# CC27x0 register map
File version: 1.0
CPU: CM4 r0p4, little endian, no MPU, no FPU, VTOR, 3 interrupt priority bits
Registers are 32-bit, read-write, reset 0x0 unless marked. A register's access mark holds for its fields unless they carry their own. Offsets are from the block's base; [hi:lo] are bit positions; {n}, {i} and the like mark numbered series; 'fields as' and 'values as' point back to an identical list.

## LRFDMDM (part 2 of 2)
Base 0x40082000
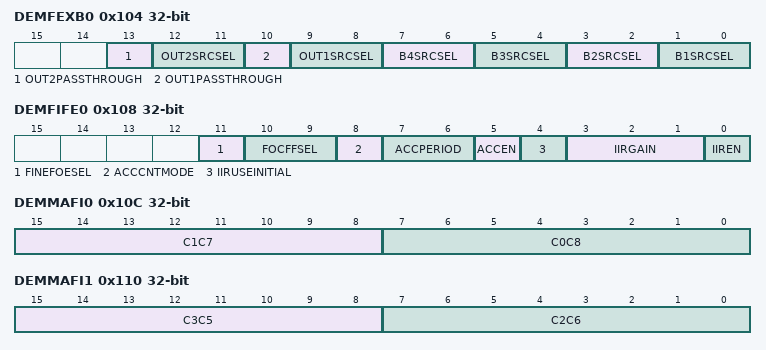
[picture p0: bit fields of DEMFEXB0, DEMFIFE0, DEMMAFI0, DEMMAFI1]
0x104 DEMFEXB0 — Internal. Only to be used through TI provided API.
  [13] OUT2PASSTHROUGH — Internal. Only to be used through TI provided API.
    1=ONE (Internal. Only to be used through TI provided API.); 0=ZERO (Internal. Only to be used through TI provided API.)
  [12:11] OUT2SRCSEL — Internal. Only to be used through TI provided API.
    2=BDE1 (Internal. Only to be used through TI provided API.); 1=CMIX (Internal. Only to be used through TI provided API.); 0=CODC (Internal. Only to be used through TI provided API.)
  [10] OUT1PASSTHROUGH — Internal. Only to be used through TI provided API.
    values as OUT2PASSTHROUGH
  [9:8] OUT1SRCSEL — Internal. Only to be used through TI provided API.
    values as OUT2SRCSEL
  [7:6] B4SRCSEL — Internal. Only to be used through TI provided API.
    3=ONES (Internal. Only to be used through TI provided API.); 0=ZEROS (Internal. Only to be used through TI provided API.)
  [5:4] B3SRCSEL — Internal. Only to be used through TI provided API.
    2=CMIX (Internal. Only to be used through TI provided API.); 1=CODC (Internal. Only to be used through TI provided API.); 0=INPUT (Internal. Only to be used through TI provided API.)
  [3:2] B2SRCSEL — Internal. Only to be used through TI provided API.
    2=BDE1 (Internal. Only to be used through TI provided API.); 1=CODC (Internal. Only to be used through TI provided API.); 0=INPUT (Internal. Only to be used through TI provided API.)
  [1:0] B1SRCSEL — Internal. Only to be used through TI provided API.
    2=BDE1 (Internal. Only to be used through TI provided API.); 1=CMIX (Internal. Only to be used through TI provided API.); 0=INPUT (Internal. Only to be used through TI provided API.)
0x108 DEMFIFE0 — Internal. Only to be used through TI provided API.
  [11] FINEFOESEL — Internal. Only to be used through TI provided API.
    1=ACC (Internal. Only to be used through TI provided API.); 0=IIR (Internal. Only to be used through TI provided API.)
  [10:9] FOCFFSEL — Internal. Only to be used through TI provided API.
    2=MANUAL (Internal. Only to be used through TI provided API.); 1=ACC (Internal. Only to be used through TI provided API.); 0=IIR (Internal. Only to be used through TI provided API.)
  [8] ACCCNTMODE — Internal. Only to be used through TI provided API.
    1=CONT (Internal. Only to be used through TI provided API.); 0=SINGLE (Internal. Only to be used through TI provided API.)
  [7:6] ACCPERIOD — Internal. Only to be used through TI provided API.
    3=PER512 (Internal. Only to be used through TI provided API.); 2=PER256 (Internal. Only to be used through TI provided API.); 1=PER128 (Internal. Only to be used through TI provided API.); 0=PER64 (Internal. Only to be used through TI provided API.)
  [5] ACCEN — Internal. Only to be used through TI provided API.
    1=ON (Internal. Only to be used through TI provided API.); 0=OFF (Internal. Only to be used through TI provided API.)
  [4] IIRUSEINITIAL — Internal. Only to be used through TI provided API.
    1=EN (Internal. Only to be used through TI provided API.); 0=DIS (Internal. Only to be used through TI provided API.)
  [3:1] IIRGAIN — Internal. Only to be used through TI provided API.
    7=DIV1024 (Internal. Only to be used through TI provided API.); 6=DIV512 (Internal. Only to be used through TI provided API.); 5=DIV256 (Internal. Only to be used through TI provided API.); 4=DIV128 (Internal. Only to be used through TI provided API.); 3=DIV64 (Internal. Only to be used through TI provided API.); 2=DIV32 (Internal. Only to be used through TI provided API.); 1=DIV16 (Internal. Only to be used through TI provided API.); 0=OFF (Internal. Only to be used through TI provided API.)
  [0] IIREN — Internal. Only to be used through TI provided API.
    values as ACCEN
0x10C DEMMAFI0 — Internal. Only to be used through TI provided API.
  [15:8] C1C7 — Internal. Only to be used through TI provided API.
    255=ALLONES (Internal. Only to be used through TI provided API.); 0=ALLZEROS (Internal. Only to be used through TI provided API.)
  [7:0] C0C8 — Internal. Only to be used through TI provided API.
    values as C1C7
0x110 DEMMAFI1 — Internal. Only to be used through TI provided API.
  [15:8] C3C5 — Internal. Only to be used through TI provided API.
    values as DEMMAFI0.C1C7
  [7:0] C2C6 — Internal. Only to be used through TI provided API.
    values as DEMMAFI0.C1C7
0x114 DEMMAFI2 — Internal. Only to be used through TI provided API.
  [8:0] C4
    0x1FF=ALLONES (Internal. Only to be used through TI provided API.); 0=ALLZEROS (Internal. Only to be used through TI provided API.)
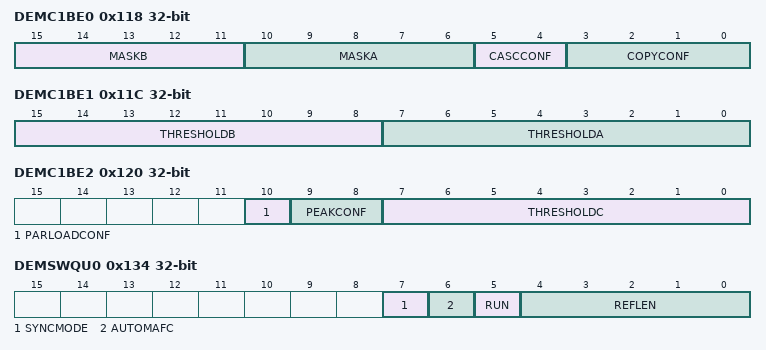
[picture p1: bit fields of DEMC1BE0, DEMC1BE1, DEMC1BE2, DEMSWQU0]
0x118 DEMC1BE0 — Internal. Only to be used through TI provided API.
  [15:11] MASKB — Internal. Only to be used through TI provided API.
    31=ALLONES (Internal. Only to be used through TI provided API.); 0=ALLZEROS (Internal. Only to be used through TI provided API.)
  [10:6] MASKA — Internal. Only to be used through TI provided API.
    values as MASKB
  [5:4] CASCCONF — Internal. Only to be used through TI provided API.
    2=PARALLEL (Internal. Only to be used through TI provided API.); 1=SERIAL (Internal. Only to be used through TI provided API.); 0=SINGLE (Internal. Only to be used through TI provided API.)
  [3:0] COPYCONF — Internal. Only to be used through TI provided API.
    15=ALLONES (Internal. Only to be used through TI provided API.); 0=ALLZEROS (Internal. Only to be used through TI provided API.)
0x11C DEMC1BE1 — Internal. Only to be used through TI provided API.
  [15:8] THRESHOLDB — Internal. Only to be used through TI provided API.
    values as DEMMAFI0.C1C7
  [7:0] THRESHOLDA — Internal. Only to be used through TI provided API.
    values as DEMMAFI0.C1C7
0x120 DEMC1BE2 — Internal. Only to be used through TI provided API.
  [10] PARLOADCONF — Internal. Only to be used through TI provided API.
    1=ATOD (Internal. Only to be used through TI provided API.); 0=ATOB (Internal. Only to be used through TI provided API.)
  [9:8] PEAKCONF — Internal. Only to be used through TI provided API.
    2=BESTAB (Internal. Only to be used through TI provided API.); 1=BEST (Internal. Only to be used through TI provided API.); 0=THRESH (Internal. Only to be used through TI provided API.)
  [7:0] THRESHOLDC — Internal. Only to be used through TI provided API.
    values as DEMMAFI0.C1C7
{0x124+4i} SPARE{i} (i=0..3) — Internal. Only to be used through TI provided API.
  [15:0] VAL
    0xFFFF=ALLONES (Internal. Only to be used through TI provided API.); 0=ALLZEROS (Internal. Only to be used through TI provided API.)
0x134 DEMSWQU0 — Internal. Only to be used through TI provided API.
  [7] SYNCMODE — Internal. Only to be used through TI provided API.
    values as DEMFEXB0.OUT2PASSTHROUGH
  [6] AUTOMAFC — Internal. Only to be used through TI provided API.
    values as DEMFIFE0.ACCEN
  [5] RUN — Internal. Only to be used through TI provided API.
    values as DEMFIFE0.ACCEN
  [4:0] REFLEN — Internal. Only to be used through TI provided API.
    values as DEMC1BE0.MASKB
0x138 DEMC1BEREF0 — Internal. Only to be used through TI provided API.
  [15:0] CAR15C0
    values as SPARE0.VAL
0x13C DEMC1BEREF1 — Internal. Only to be used through TI provided API.
  [15:0] CAR31C16
    values as SPARE0.VAL
0x140 DEMC1BEREF2 — Internal. Only to be used through TI provided API.
  [15:0] CBR15C0
    values as SPARE0.VAL
0x144 DEMC1BEREF3 — Internal. Only to be used through TI provided API.
  [15:0] CBR31C16
    values as SPARE0.VAL
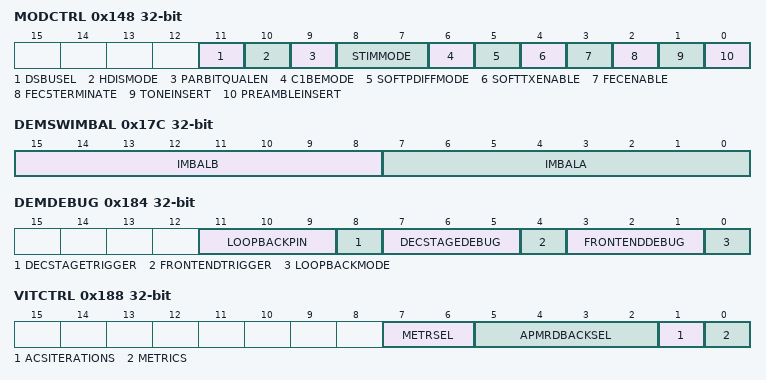
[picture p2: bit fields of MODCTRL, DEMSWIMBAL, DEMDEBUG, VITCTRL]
0x148 MODCTRL — Internal. Only to be used through TI provided API.
  [11] DSBUSEL — Internal. Only to be used through TI provided API.
    values as DEMFEXB0.OUT2PASSTHROUGH
  [10] HDISMODE — Internal. Only to be used through TI provided API.
    values as DEMFIFE0.IIRUSEINITIAL
  [9] PARBITQUALEN — Internal. Only to be used through TI provided API.
    values as DEMFIFE0.ACCEN
  [8:7] STIMMODE — Internal. Only to be used through TI provided API.
    2=EARLY (Internal. Only to be used through TI provided API.); 1=LATE (Internal. Only to be used through TI provided API.); 0=NORMAL (Internal. Only to be used through TI provided API.)
  [6] C1BEMODE — Internal. Only to be used through TI provided API.
    1=EARLYLATE (Internal. Only to be used through TI provided API.); 0=NORMAL (Internal. Only to be used through TI provided API.)
  [5] SOFTPDIFFMODE — Internal. Only to be used through TI provided API.
    values as DEMFIFE0.IIRUSEINITIAL
  [4] SOFTTXENABLE — Internal. Only to be used through TI provided API.
    values as DEMFIFE0.ACCEN
  [3] FECENABLE — Internal. Only to be used through TI provided API.
    values as DEMFIFE0.ACCEN
  [2] FEC5TERMINATE — Internal. Only to be used through TI provided API.
    values as DEMFIFE0.ACCEN
  [1] TONEINSERT — Internal. Only to be used through TI provided API.
    values as DEMFIFE0.IIRUSEINITIAL
  [0] PREAMBLEINSERT — Internal. Only to be used through TI provided API.
    values as DEMFIFE0.IIRUSEINITIAL
0x14C MODPREAMBLE — Internal. Only to be used through TI provided API.
  [15:0] WORD
    values as SPARE0.VAL
0x150 DEMFRAC0 — Internal. Only to be used through TI provided API.
  [15:0] P15C0
    values as SPARE0.VAL
0x154 DEMFRAC1 — Internal. Only to be used through TI provided API.
  [11:0] P27C16
    0xFFF=ALLONES (Internal. Only to be used through TI provided API.); 0=ALLZEROS (Internal. Only to be used through TI provided API.)
0x158 DEMFRAC2 — Internal. Only to be used through TI provided API.
  [15:0] Q15C0
    values as SPARE0.VAL
0x15C DEMFRAC3 — Internal. Only to be used through TI provided API.
  [11:0] Q27C16
    values as DEMFRAC1.P27C16
0x160 DEMCODC1 — Internal. Only to be used through TI provided API.
  [12:0] COMPIVAL
    0x1FFF=ALLONES (Internal. Only to be used through TI provided API.); 0=ALLZEROS (Internal. Only to be used through TI provided API.)
0x164 DEMCODC2 — Internal. Only to be used through TI provided API.
  [12:0] COMPQVAL
    values as DEMCODC1.COMPIVAL
0x168 DEMFIDC1 — Internal. Only to be used through TI provided API.
  fields as DEMCODC1
0x16C DEMFIDC2 — Internal. Only to be used through TI provided API.
  fields as DEMCODC2
0x170 DEMFIFE1 — Internal. Only to be used through TI provided API.
  [7:0] FOCFBREGVAL
    values as DEMMAFI0.C1C7
0x174 DEMMAFC0 — Internal. Only to be used through TI provided API.
  [7:0] COMPVAL
    values as DEMMAFI0.C1C7
0x178 DEMMAFI4 — Internal. Only to be used through TI provided API.
  [7:0] TERMVAL
    values as DEMMAFI0.C1C7
0x17C DEMSWIMBAL — Internal. Only to be used through TI provided API.
  [15:8] IMBALB — Internal. Only to be used through TI provided API.
    values as DEMMAFI0.C1C7
  [7:0] IMBALA — Internal. Only to be used through TI provided API.
    values as DEMMAFI0.C1C7
0x180 DEMSOFTPDIFF — Internal. Only to be used through TI provided API.
  [7:0] VAL
    values as DEMMAFI0.C1C7
0x184 DEMDEBUG — Internal. Only to be used through TI provided API.
  [11:9] LOOPBACKPIN — Internal. Only to be used through TI provided API.
    {v}=GPI{v} (Internal. Only to be used through TI provided API.) (v=0..7)
  [8] DECSTAGETRIGGER — Internal. Only to be used through TI provided API.
    values as DEMFEXB0.OUT2PASSTHROUGH
  [7:5] DECSTAGEDEBUG — Internal. Only to be used through TI provided API.
    7=SOFD (Internal. Only to be used through TI provided API.); 6=STIM (Internal. Only to be used through TI provided API.); 5=MAFC (Internal. Only to be used through TI provided API.); 4=C1BE (Internal. Only to be used through TI provided API.); 3=MAFI (Internal. Only to be used through TI provided API.); 2=FIFE (Internal. Only to be used through TI provided API.); 1=PDIF (Internal. Only to be used through TI provided API.); 0=NOSEL (Internal. Only to be used through TI provided API.)
  [4] FRONTENDTRIGGER — Internal. Only to be used through TI provided API.
    values as DEMFEXB0.OUT2PASSTHROUGH
  [3:1] FRONTENDDEBUG — Internal. Only to be used through TI provided API.
    7=FIDC (Internal. Only to be used through TI provided API.); 6=FRAC (Internal. Only to be used through TI provided API.); 5=CHFI (Internal. Only to be used through TI provided API.); 4=BDE2 (Internal. Only to be used through TI provided API.); 3=FEXB2 (Internal. Only to be used through TI provided API.); 2=BDE1 (Internal. Only to be used through TI provided API.); 1=IQMC (Internal. Only to be used through TI provided API.); 0=NOSEL (Internal. Only to be used through TI provided API.)
  [0] LOOPBACKMODE — Internal. Only to be used through TI provided API.
    values as DEMFEXB0.OUT2PASSTHROUGH
0x188 VITCTRL — Internal. Only to be used through TI provided API.
  [7:6] METRSEL — Internal. Only to be used through TI provided API.
    3=MLSE (Internal. Only to be used through TI provided API.); 2=SOFD (Internal. Only to be used through TI provided API.); 1=PHAC (Internal. Only to be used through TI provided API.); 0=MET5M (Internal. Only to be used through TI provided API.)
  [5:2] APMRDBACKSEL — Internal. Only to be used through TI provided API.
    {v}=APM{v-8} (Internal. Only to be used through TI provided API.) (v=8..15); 0=NOSEL (Internal. Only to be used through TI provided API.)
  [1] ACSITERATIONS — Internal. Only to be used through TI provided API.
    1=CODE23 (Internal. Only to be used through TI provided API.); 0=CODE12 (Internal. Only to be used through TI provided API.)
  [0] METRICS — Internal. Only to be used through TI provided API.
    1=SOFT (Internal. Only to be used through TI provided API.); 0=HW (Internal. Only to be used through TI provided API.)
0x18C VITCOMPUTE wo — Internal. Only to be used through TI provided API.
  [0] START
    values as DEMFEXB0.OUT2PASSTHROUGH
0x190 VITAPMRDBACK ro — Internal. Only to be used through TI provided API.
  [9:0] VALUE
    0x3FF=ALLONES (Internal. Only to be used through TI provided API.); 0=ALLZEROS (Internal. Only to be used through TI provided API.)
0x194 VITSTATE ro — Internal. Only to be used through TI provided API.
  [2:0] VALUE
    7=ALLONES (Internal. Only to be used through TI provided API.); 0=ALLZEROS (Internal. Only to be used through TI provided API.)
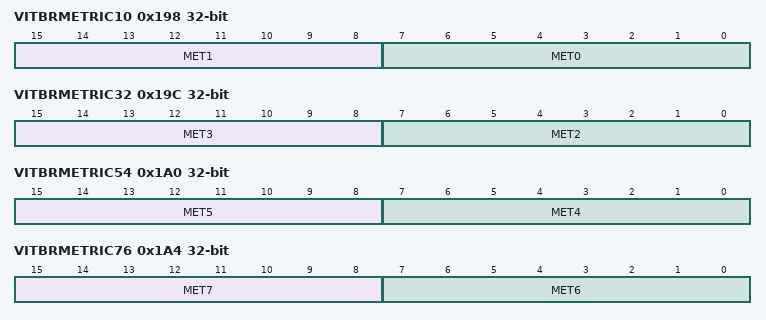
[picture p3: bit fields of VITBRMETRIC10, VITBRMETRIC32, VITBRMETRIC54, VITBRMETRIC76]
0x198 VITBRMETRIC10 — Internal. Only to be used through TI provided API.
  [15:8] MET1 — Internal. Only to be used through TI provided API.
    values as DEMMAFI0.C1C7
  [7:0] MET0 — Internal. Only to be used through TI provided API.
    values as DEMMAFI0.C1C7
0x19C VITBRMETRIC32 — Internal. Only to be used through TI provided API.
  [15:8] MET3 — Internal. Only to be used through TI provided API.
    values as DEMMAFI0.C1C7
  [7:0] MET2 — Internal. Only to be used through TI provided API.
    values as DEMMAFI0.C1C7
0x1A0 VITBRMETRIC54 — Internal. Only to be used through TI provided API.
  [15:8] MET5 — Internal. Only to be used through TI provided API.
    values as DEMMAFI0.C1C7
  [7:0] MET4 — Internal. Only to be used through TI provided API.
    values as DEMMAFI0.C1C7
0x1A4 VITBRMETRIC76 — Internal. Only to be used through TI provided API.
  [15:8] MET7 — Internal. Only to be used through TI provided API.
    values as DEMMAFI0.C1C7
  [7:0] MET6 — Internal. Only to be used through TI provided API.
    values as DEMMAFI0.C1C7
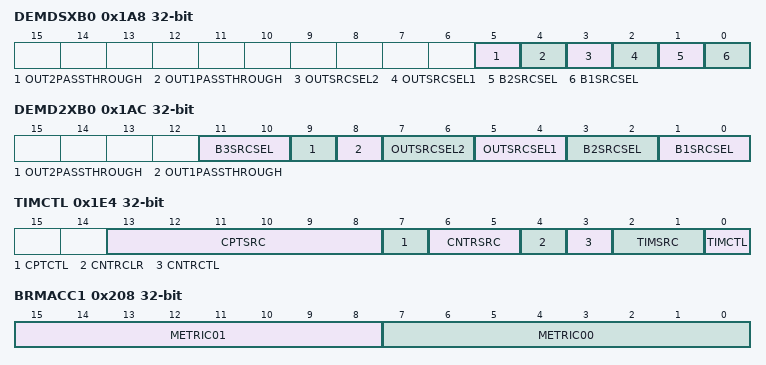
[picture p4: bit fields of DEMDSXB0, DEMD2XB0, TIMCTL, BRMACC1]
0x1A8 DEMDSXB0 — Internal. Only to be used through TI provided API.
  [5] OUT2PASSTHROUGH — Internal. Only to be used through TI provided API.
    values as DEMFEXB0.OUT2PASSTHROUGH
  [4] OUT1PASSTHROUGH — Internal. Only to be used through TI provided API.
    values as DEMFEXB0.OUT2PASSTHROUGH
  [3] OUTSRCSEL2 — Internal. Only to be used through TI provided API.
    1=MAFI (Internal. Only to be used through TI provided API.); 0=FIFE (Internal. Only to be used through TI provided API.)
  [2] OUTSRCSEL1 — Internal. Only to be used through TI provided API.
    values as OUTSRCSEL2
  [1] B2SRCSEL — Internal. Only to be used through TI provided API.
    1=FIFE (Internal. Only to be used through TI provided API.); 0=INPUT (Internal. Only to be used through TI provided API.)
  [0] B1SRCSEL — Internal. Only to be used through TI provided API.
    1=MAFI (Internal. Only to be used through TI provided API.); 0=INPUT (Internal. Only to be used through TI provided API.)
0x1AC DEMD2XB0 — Internal. Only to be used through TI provided API.
  [11:10] B3SRCSEL — Internal. Only to be used through TI provided API.
    2=STIM (Internal. Only to be used through TI provided API.); 1=MAFC (Internal. Only to be used through TI provided API.); 0=INPUT (Internal. Only to be used through TI provided API.)
  [9] OUT2PASSTHROUGH — Internal. Only to be used through TI provided API.
  [8] OUT1PASSTHROUGH — Internal. Only to be used through TI provided API.
  [7:6] OUTSRCSEL2 — Internal. Only to be used through TI provided API.
    2=PDIF2 (Internal. Only to be used through TI provided API.); 1=STIM (Internal. Only to be used through TI provided API.); 0=MAFC (Internal. Only to be used through TI provided API.)
  [5:4] OUTSRCSEL1 — Internal. Only to be used through TI provided API.
    values as OUTSRCSEL2
  [3:2] B2SRCSEL — Internal. Only to be used through TI provided API.
    2=PDIF2 (Internal. Only to be used through TI provided API.); 1=MAFC (Internal. Only to be used through TI provided API.); 0=INPUT (Internal. Only to be used through TI provided API.)
  [1:0] B1SRCSEL — Internal. Only to be used through TI provided API.
    2=PDIF2 (Internal. Only to be used through TI provided API.); 1=STIM (Internal. Only to be used through TI provided API.); 0=INPUT (Internal. Only to be used through TI provided API.)
0x1E4 TIMCTL — Internal. Only to be used through TI provided API.
  [13:8] CPTSRC — Internal. Only to be used through TI provided API.
    63=ALLONES (Internal. Only to be used through TI provided API.); 0=ALLZEROS (Internal. Only to be used through TI provided API.)
  [7] CPTCTL — Internal. Only to be used through TI provided API.
    values as DEMFIFE0.IIRUSEINITIAL
  [6:5] CNTRSRC — Internal. Only to be used through TI provided API.
    3=CLK4BAUDF (Internal. Only to be used through TI provided API.); 2=CLK4BAUD (Internal. Only to be used through TI provided API.); 1=CLKBAUD (Internal. Only to be used through TI provided API.); 0=CLK (Internal. Only to be used through TI provided API.)
  [4] CNTRCLR — Internal. Only to be used through TI provided API.
    values as DEMFEXB0.OUT2PASSTHROUGH
  [3] CNTRCTL — Internal. Only to be used through TI provided API.
    values as DEMFEXB0.OUT2PASSTHROUGH
  [2:1] TIMSRC — Internal. Only to be used through TI provided API.
    values as CNTRSRC
  [0] TIMCTL — Internal. Only to be used through TI provided API.
    values as DEMFIFE0.IIRUSEINITIAL
0x1E8 TIMINC — Internal. Only to be used through TI provided API.
  fields as SPARE0
0x1EC TIMPER — Internal. Only to be used through TI provided API.
  fields as SPARE0
0x1F0 TIMCNT ro — Internal. Only to be used through TI provided API.
  fields as SPARE0
0x1F4 TIMCAPT ro — Internal. Only to be used through TI provided API.
  [15:0] VALUE
    values as SPARE0.VAL
0x1F8 TIMEBASE wo — Internal. Only to be used through TI provided API.
  [0] FLUSH
    values as DEMFEXB0.OUT2PASSTHROUGH
0x1FC COUNT1IN — Internal. Only to be used through TI provided API.
  fields as SPARE0
0x200 COUNT1RES ro — Internal. Only to be used through TI provided API.
  [4:0] VAL
    values as DEMC1BE0.MASKB
0x208 BRMACC1 ro — Internal. Only to be used through TI provided API.
  [15:8] METRIC01 — Internal. Only to be used through TI provided API.
    values as DEMMAFI0.C1C7
  [7:0] METRIC00 — Internal. Only to be used through TI provided API.
    values as DEMMAFI0.C1C7
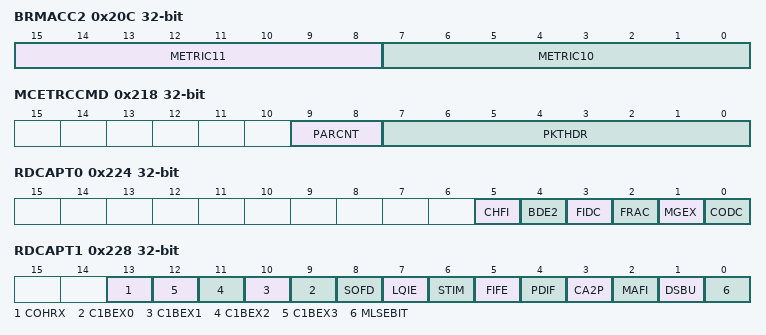
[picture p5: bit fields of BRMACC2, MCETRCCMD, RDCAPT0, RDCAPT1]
0x20C BRMACC2 ro — Internal. Only to be used through TI provided API.
  [15:8] METRIC11 — Internal. Only to be used through TI provided API.
    values as DEMMAFI0.C1C7
  [7:0] METRIC10 — Internal. Only to be used through TI provided API.
    values as DEMMAFI0.C1C7
0x210 MCETRCCTRL wo — Internal. Only to be used through TI provided API.
  [0] SEND
    values as DEMFEXB0.OUT2PASSTHROUGH
0x214 MCETRCSTAT ro — Internal. Only to be used through TI provided API.
  [0] BUSY
    values as DEMFEXB0.OUT2PASSTHROUGH
0x218 MCETRCCMD — Internal. Only to be used through TI provided API.
  [9:8] PARCNT — Internal. Only to be used through TI provided API.
    3=ALLONES (Internal. Only to be used through TI provided API.); 0=ALLZEROS (Internal. Only to be used through TI provided API.)
  [7:0] PKTHDR — Internal. Only to be used through TI provided API.
    values as DEMMAFI0.C1C7
0x21C MCETRCPAR0 — Internal. Only to be used through TI provided API.
  fields as SPARE0
0x220 MCETRCPAR1 — Internal. Only to be used through TI provided API.
  fields as SPARE0
0x224 RDCAPT0 wo — Internal. Only to be used through TI provided API.
  [all] fields
    values as DEMFEXB0.OUT2PASSTHROUGH
  [5] CHFI — Internal. Only to be used through TI provided API.
  [4] BDE2 — Internal. Only to be used through TI provided API.
  [3] FIDC — Internal. Only to be used through TI provided API.
  [2] FRAC — Internal. Only to be used through TI provided API.
  [1] MGEX — Internal. Only to be used through TI provided API.
  [0] CODC — Internal. Only to be used through TI provided API.
0x228 RDCAPT1 wo — Internal. Only to be used through TI provided API.
  [all] fields
    values as DEMFEXB0.OUT2PASSTHROUGH
  [13] COHRX — Internal. Only to be used through TI provided API.
  [n+9] C1BEX{n} (n=0..3) — Internal. Only to be used through TI provided API.
  [8] SOFD — Internal. Only to be used through TI provided API.
  [7] LQIE — Internal. Only to be used through TI provided API.
  [6] STIM — Internal. Only to be used through TI provided API.
  [5] FIFE — Internal. Only to be used through TI provided API.
  [4] PDIF — Internal. Only to be used through TI provided API.
  [3] CA2P — Internal. Only to be used through TI provided API.
  [2] MAFI — Internal. Only to be used through TI provided API.
  [1] DSBU — Internal. Only to be used through TI provided API.
  [0] MLSEBIT — Internal. Only to be used through TI provided API.
0x22C FECAPT0 — Internal. Only to be used through TI provided API.
  [12:0] VAL
    values as DEMCODC1.COMPIVAL
0x230 FECAPT1 — Internal. Only to be used through TI provided API.
  fields as FECAPT0
{0x234+4i} DSCAPT{i} (i=0..3) — Internal. Only to be used through TI provided API.
  fields as DEMSOFTPDIFF
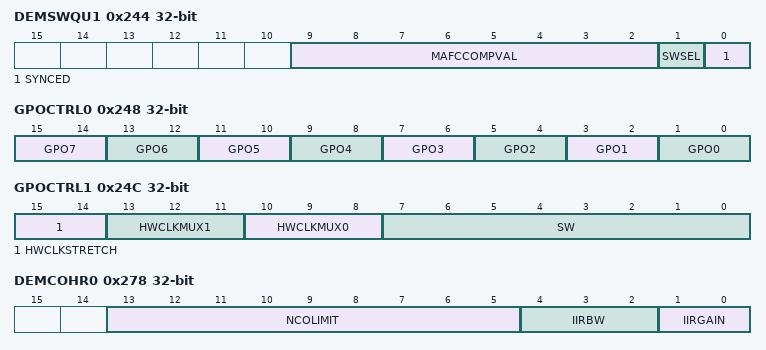
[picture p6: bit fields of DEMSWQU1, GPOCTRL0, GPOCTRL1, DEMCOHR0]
0x244 DEMSWQU1 — Internal. Only to be used through TI provided API.
  [9:2] MAFCCOMPVAL ro — Internal. Only to be used through TI provided API.
    values as DEMMAFI0.C1C7
  [1] SWSEL ro — Internal. Only to be used through TI provided API.
    1=B (Internal. Only to be used through TI provided API.); 0=A (Internal. Only to be used through TI provided API.)
  [0] SYNCED ro — Internal. Only to be used through TI provided API.
    values as DEMFEXB0.OUT2PASSTHROUGH
0x248 GPOCTRL0 — Internal. Only to be used through TI provided API.
  [15:14] GPO7 — Internal. Only to be used through TI provided API.
    3=THREE (Internal. Only to be used through TI provided API.); 2=TWO (Internal. Only to be used through TI provided API.); 1=TOPSM_WAIT (Internal. Only to be used through TI provided API.); 0=SW7 (Internal. Only to be used through TI provided API.)
  [13:12] GPO6 — Internal. Only to be used through TI provided API.
    3=THREE (Internal. Only to be used through TI provided API.); 2=TWO (Internal. Only to be used through TI provided API.); 1=TRANSPARENT_OUT (Internal. Only to be used through TI provided API.); 0=SW6 (Internal. Only to be used through TI provided API.)
  [11:10] GPO5 — Internal. Only to be used through TI provided API.
    3=THREE (Internal. Only to be used through TI provided API.); 2=TWO (Internal. Only to be used through TI provided API.); 1=DEM_OUT_WORD (Internal. Only to be used through TI provided API.); 0=SW5 (Internal. Only to be used through TI provided API.)
  [9:8] GPO4 — Internal. Only to be used through TI provided API.
    3=THREE (Internal. Only to be used through TI provided API.); 2=TWO (Internal. Only to be used through TI provided API.); 1=CORR_PEAK_C (Internal. Only to be used through TI provided API.); 0=SW4 (Internal. Only to be used through TI provided API.)
  [7:6] GPO3 — Internal. Only to be used through TI provided API.
    3=THREE (Internal. Only to be used through TI provided API.); 2=TWO (Internal. Only to be used through TI provided API.); 1=CORR_PEAK_B (Internal. Only to be used through TI provided API.); 0=SW3 (Internal. Only to be used through TI provided API.)
  [5:4] GPO2 — Internal. Only to be used through TI provided API.
    3=THREE (Internal. Only to be used through TI provided API.); 2=TWO (Internal. Only to be used through TI provided API.); 1=CORR_PEAK_A (Internal. Only to be used through TI provided API.); 0=SW2 (Internal. Only to be used through TI provided API.)
  [3:2] GPO1 — Internal. Only to be used through TI provided API.
    3=THREE (Internal. Only to be used through TI provided API.); 2=TWO (Internal. Only to be used through TI provided API.); 1=HWCLK1 (Internal. Only to be used through TI provided API.); 0=SW1 (Internal. Only to be used through TI provided API.)
  [1:0] GPO0 — Internal. Only to be used through TI provided API.
    3=THREE (Internal. Only to be used through TI provided API.); 2=LOOPBACK (Internal. Only to be used through TI provided API.); 1=HWCLK0 (Internal. Only to be used through TI provided API.); 0=SW0 (Internal. Only to be used through TI provided API.)
0x24C GPOCTRL1 — Internal. Only to be used through TI provided API.
  [all] fields
    values as DEMFEXB0.OUT2PASSTHROUGH
  [15:14] HWCLKSTRETCH — Internal. Only to be used through TI provided API.
  [13:11] HWCLKMUX1 — Internal. Only to be used through TI provided API.
  [10:8] HWCLKMUX0 — Internal. Only to be used through TI provided API.
  [7:0] SW — Internal. Only to be used through TI provided API.
0x250 RFERSSI ro — Internal. Only to be used through TI provided API.
  fields as DEMSOFTPDIFF
0x254 RFEMAXRSSI ro — Internal. Only to be used through TI provided API.
  fields as DEMSOFTPDIFF
0x258 RFEDBGAIN ro — Internal. Only to be used through TI provided API.
  fields as DEMSOFTPDIFF
0x25C SYNC0 ro — Internal. Only to be used through TI provided API.
  [15:0] SWA15C0
    values as SPARE0.VAL
0x260 SYNC1 ro — Internal. Only to be used through TI provided API.
  [15:0] SWA31C16
    values as SPARE0.VAL
0x264 SYNC2 ro — Internal. Only to be used through TI provided API.
  [15:0] SWB15C0
    values as SPARE0.VAL
0x268 SYNC3 ro — Internal. Only to be used through TI provided API.
  [15:0] SWB31C16
    values as SPARE0.VAL
0x274 DEMHDIS0 ro — Internal. Only to be used through TI provided API.
  [7:0] VAL
0x278 DEMCOHR0 — Internal. Only to be used through TI provided API.
  [13:5] NCOLIMIT — Internal. Only to be used through TI provided API.
  [4:2] IIRBW — Internal. Only to be used through TI provided API.
  [1:0] IIRGAIN — Internal. Only to be used through TI provided API.
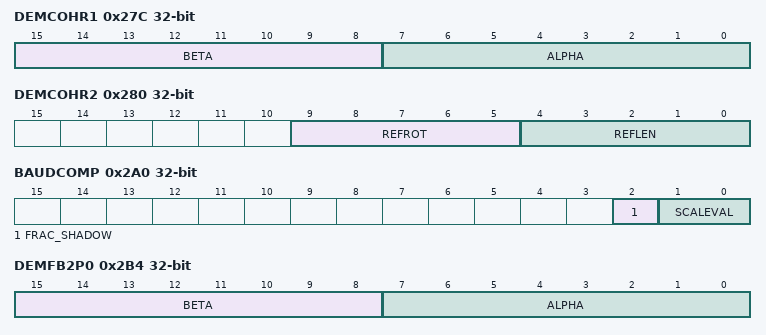
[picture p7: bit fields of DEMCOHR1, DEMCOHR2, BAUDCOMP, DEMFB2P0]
0x27C DEMCOHR1 — Internal. Only to be used through TI provided API.
  [15:8] BETA — Internal. Only to be used through TI provided API.
  [7:0] ALPHA — Internal. Only to be used through TI provided API.
0x280 DEMCOHR2 — Internal. Only to be used through TI provided API.
  [9:5] REFROT — Internal. Only to be used through TI provided API.
  [4:0] REFLEN — Internal. Only to be used through TI provided API.
0x284 DEMCOHR3 — Internal. Only to be used through TI provided API.
  [15:0] REF150
0x288 DEMCOHR4 — Internal. Only to be used through TI provided API.
  [15:0] REF3116
0x28C DEMCOHR5 ro — Internal. Only to be used through TI provided API.
  [15:0] VAL
0x290 DEMCOHR6 ro — Internal. Only to be used through TI provided API.
  [5:0] VAL
0x294 DEMCOHR7 ro — Internal. Only to be used through TI provided API.
  [3:0] VAL
0x298 DEMCOHR8 ro — Internal. Only to be used through TI provided API.
  [5:0] VAL
0x29C DEMCOHR9 ro — Internal. Only to be used through TI provided API.
  [12:0] VAL
0x2A0 BAUDCOMP — Internal. Only to be used through TI provided API.
  [2] FRAC_SHADOW — Internal. Only to be used through TI provided API.
  [1:0] SCALEVAL — Internal. Only to be used through TI provided API.
0x2B0 DEMCMIX2 — Internal. Only to be used through TI provided API.
  [12:0] N
0x2B4 DEMFB2P0 — Internal. Only to be used through TI provided API.
  fields as DEMCOHR1
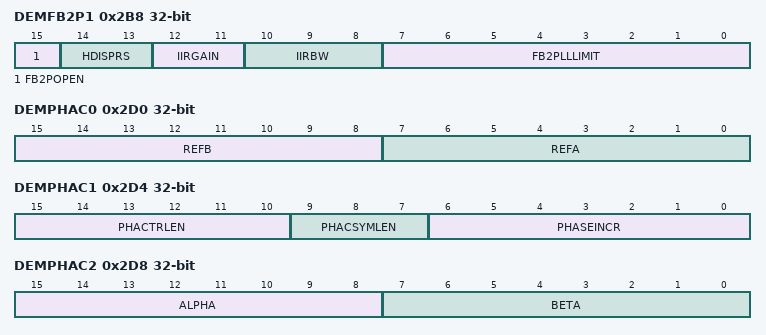
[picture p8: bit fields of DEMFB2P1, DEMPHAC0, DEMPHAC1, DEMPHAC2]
0x2B8 DEMFB2P1 — Internal. Only to be used through TI provided API.
  [15] FB2POPEN — Internal. Only to be used through TI provided API.
  [14:13] HDISPRS — Internal. Only to be used through TI provided API.
  [12:11] IIRGAIN — Internal. Only to be used through TI provided API.
  [10:8] IIRBW — Internal. Only to be used through TI provided API.
  [7:0] FB2PLLLIMIT — Internal. Only to be used through TI provided API.
0x2BC DEMFB2P2 — Internal. Only to be used through TI provided API.
  [10:0] RBP ro
0x2C4 DEMDSBU0 ro reset 0x1FF — Internal. Only to be used through TI provided API.
  [8:0] RDPOUT
0x2C8 DEMDSBU1 ro — Internal. Only to be used through TI provided API.
  [15:0] AVGVAL
0x2CC DEMDSBU3 ro — Internal. Only to be used through TI provided API.
  [8:0] WRPOUT
0x2D0 DEMPHAC0 — Internal. Only to be used through TI provided API.
  [15:8] REFB — Internal. Only to be used through TI provided API.
  [7:0] REFA — Internal. Only to be used through TI provided API.
0x2D4 DEMPHAC1 — Internal. Only to be used through TI provided API.
  [15:10] PHACTRLEN — Internal. Only to be used through TI provided API.
  [9:7] PHACSYMLEN — Internal. Only to be used through TI provided API.
  [6:0] PHASEINCR — Internal. Only to be used through TI provided API.
0x2D8 DEMPHAC2 — Internal. Only to be used through TI provided API.
  [15:8] ALPHA — Internal. Only to be used through TI provided API.
  [7:0] BETA — Internal. Only to be used through TI provided API.
0x2DC DEMPHAC3 — Internal. Only to be used through TI provided API.
  [1:0] IIRBW
0x2E0 DEMPHAC4 — Internal. Only to be used through TI provided API.
  [15:0] TR150
{0x2D0+4i} DEMPHAC{i} (i=5..7) — Internal. Only to be used through TI provided API.
  [15:0] TR{1616i-4964}
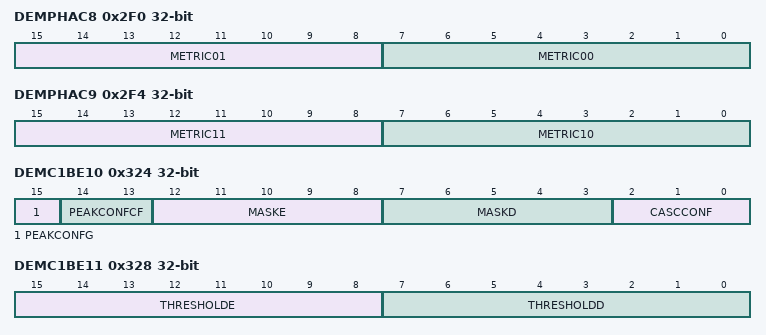
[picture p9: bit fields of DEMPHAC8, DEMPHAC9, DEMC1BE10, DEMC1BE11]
0x2F0 DEMPHAC8 ro — Internal. Only to be used through TI provided API.
  [15:8] METRIC01 — Internal. Only to be used through TI provided API.
  [7:0] METRIC00 — Internal. Only to be used through TI provided API.
0x2F4 DEMPHAC9 ro — Internal. Only to be used through TI provided API.
  [15:8] METRIC11 — Internal. Only to be used through TI provided API.
  [7:0] METRIC10 — Internal. Only to be used through TI provided API.
0x2F8 DEMC1BEREF4 — Internal. Only to be used through TI provided API.
  [15:0] CDR15C0
0x2FC DEMC1BEREF5 — Internal. Only to be used through TI provided API.
  [15:0] CDR31C16
0x300 DEMC1BEREF6 — Internal. Only to be used through TI provided API.
  [15:0] CER15C0
0x304 DEMC1BEREF7 — Internal. Only to be used through TI provided API.
  [15:0] CER31C16
0x308 DEMC1BE3 ro — Internal. Only to be used through TI provided API.
  [15:0] CORRVALUEA
0x30C DEMC1BE4 ro — Internal. Only to be used through TI provided API.
  [15:0] CORRVALUEB
0x310 DEMC1BE5 ro — Internal. Only to be used through TI provided API.
  [15:0] CORRVALUEC
{0x2FC+4i} DEMC1BE{i} ro (i=6..9) — Internal. Only to be used through TI provided API.
  [7:0] VAL
0x324 DEMC1BE10 — Internal. Only to be used through TI provided API.
  [15] PEAKCONFG — Internal. Only to be used through TI provided API.
  [14:13] PEAKCONFCF — Internal. Only to be used through TI provided API.
    values as DEMC1BE2.PEAKCONF
  [12:8] MASKE — Internal. Only to be used through TI provided API.
  [7:3] MASKD — Internal. Only to be used through TI provided API.
  [2:0] CASCCONF — Internal. Only to be used through TI provided API.
    5=SINGLE2 (Internal. Only to be used through TI provided API.); 4=SERIAL2 (Internal. Only to be used through TI provided API.); 3=SINGLE (Internal. Only to be used through TI provided API.); 2=PARALLEL (Internal. Only to be used through TI provided API.); 1=SERIAL (Internal. Only to be used through TI provided API.); 0=DISABLED (Internal. Only to be used through TI provided API.)
0x328 DEMC1BE11 — Internal. Only to be used through TI provided API.
  [15:8] THRESHOLDE — Internal. Only to be used through TI provided API.
  [7:0] THRESHOLDD — Internal. Only to be used through TI provided API.
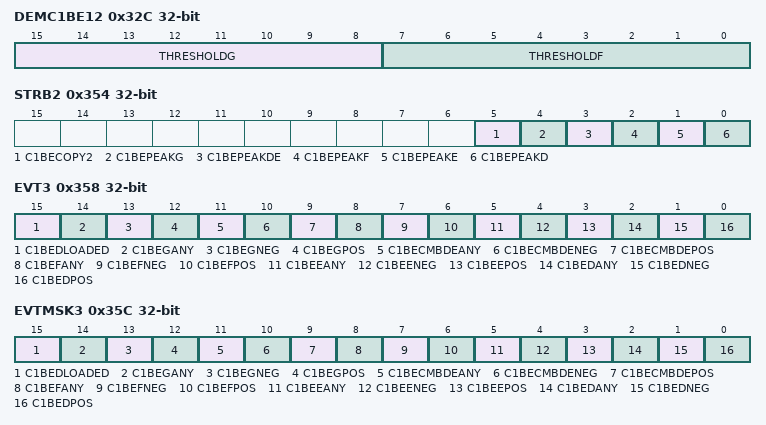
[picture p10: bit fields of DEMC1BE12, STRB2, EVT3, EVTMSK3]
0x32C DEMC1BE12 — Internal. Only to be used through TI provided API.
  [15:8] THRESHOLDG — Internal. Only to be used through TI provided API.
  [7:0] THRESHOLDF — Internal. Only to be used through TI provided API.
0x330 DEMC1BE13 ro — Internal. Only to be used through TI provided API.
  [15:0] CORRVALUED
0x334 DEMC1BE14 ro — Internal. Only to be used through TI provided API.
  [15:0] CORRVALUEE
0x338 DEMC1BE15 ro — Internal. Only to be used through TI provided API.
  [15:0] CORRVALUEF
0x34C DEMC1BE20 ro — Internal. Only to be used through TI provided API.
  [15:0] CORRVALUEG
0x354 STRB2 wo — Internal. Only to be used through TI provided API.
  [all] fields
    values as DEMFEXB0.OUT2PASSTHROUGH
  [5] C1BECOPY2 — Internal. Only to be used through TI provided API.
  [4] C1BEPEAKG — Internal. Only to be used through TI provided API.
  [3] C1BEPEAKDE — Internal. Only to be used through TI provided API.
  [2] C1BEPEAKF — Internal. Only to be used through TI provided API.
  [1] C1BEPEAKE — Internal. Only to be used through TI provided API.
  [0] C1BEPEAKD — Internal. Only to be used through TI provided API.
0x358 EVT3 ro — Internal. Only to be used through TI provided API.
  [15] C1BEDLOADED — Internal. Only to be used through TI provided API.
    values as DEMFEXB0.OUT2PASSTHROUGH
  [14] C1BEGANY — Internal. Only to be used through TI provided API.
  [13] C1BEGNEG — Internal. Only to be used through TI provided API.
  [12] C1BEGPOS — Internal. Only to be used through TI provided API.
  [11] C1BECMBDEANY — Internal. Only to be used through TI provided API.
  [10] C1BECMBDENEG — Internal. Only to be used through TI provided API.
  [9] C1BECMBDEPOS — Internal. Only to be used through TI provided API.
  [8] C1BEFANY — Internal. Only to be used through TI provided API.
  [7] C1BEFNEG — Internal. Only to be used through TI provided API.
  [6] C1BEFPOS — Internal. Only to be used through TI provided API.
  [5] C1BEEANY — Internal. Only to be used through TI provided API.
  [4] C1BEENEG — Internal. Only to be used through TI provided API.
  [3] C1BEEPOS — Internal. Only to be used through TI provided API.
  [2] C1BEDANY — Internal. Only to be used through TI provided API.
  [1] C1BEDNEG — Internal. Only to be used through TI provided API.
  [0] C1BEDPOS — Internal. Only to be used through TI provided API.
0x35C EVTMSK3 — Internal. Only to be used through TI provided API.
  [15] C1BEDLOADED — Internal. Only to be used through TI provided API.
  [14] C1BEGANY — Internal. Only to be used through TI provided API.
  [13] C1BEGNEG — Internal. Only to be used through TI provided API.
  [12] C1BEGPOS — Internal. Only to be used through TI provided API.
  [11] C1BECMBDEANY — Internal. Only to be used through TI provided API.
  [10] C1BECMBDENEG — Internal. Only to be used through TI provided API.
  [9] C1BECMBDEPOS — Internal. Only to be used through TI provided API.
  [8] C1BEFANY — Internal. Only to be used through TI provided API.
  [7] C1BEFNEG — Internal. Only to be used through TI provided API.
  [6] C1BEFPOS — Internal. Only to be used through TI provided API.
  [5] C1BEEANY — Internal. Only to be used through TI provided API.
  [4] C1BEENEG — Internal. Only to be used through TI provided API.
  [3] C1BEEPOS — Internal. Only to be used through TI provided API.
  [2] C1BEDANY — Internal. Only to be used through TI provided API.
  [1] C1BEDNEG — Internal. Only to be used through TI provided API.
  [0] C1BEDPOS — Internal. Only to be used through TI provided API.
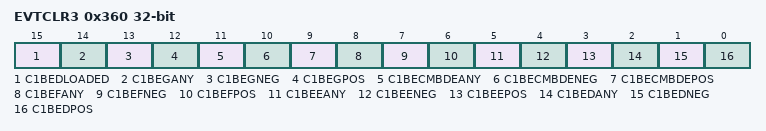
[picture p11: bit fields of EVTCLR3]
0x360 EVTCLR3 — Internal. Only to be used through TI provided API.
  [15] C1BEDLOADED wo — Internal. Only to be used through TI provided API.
  [14] C1BEGANY wo — Internal. Only to be used through TI provided API.
  [13] C1BEGNEG wo — Internal. Only to be used through TI provided API.
  [12] C1BEGPOS wo — Internal. Only to be used through TI provided API.
  [11] C1BECMBDEANY wo — Internal. Only to be used through TI provided API.
  [10] C1BECMBDENEG wo — Internal. Only to be used through TI provided API.
  [9] C1BECMBDEPOS wo — Internal. Only to be used through TI provided API.
  [8] C1BEFANY wo — Internal. Only to be used through TI provided API.
  [7] C1BEFNEG wo — Internal. Only to be used through TI provided API.
  [6] C1BEFPOS wo — Internal. Only to be used through TI provided API.
  [5] C1BEEANY wo — Internal. Only to be used through TI provided API.
  [4] C1BEENEG wo — Internal. Only to be used through TI provided API.
  [3] C1BEEPOS wo — Internal. Only to be used through TI provided API.
  [2] C1BEDANY wo — Internal. Only to be used through TI provided API.
  [1] C1BEDNEG wo — Internal. Only to be used through TI provided API.
  [0] C1BEDPOS wo — Internal. Only to be used through TI provided API.
